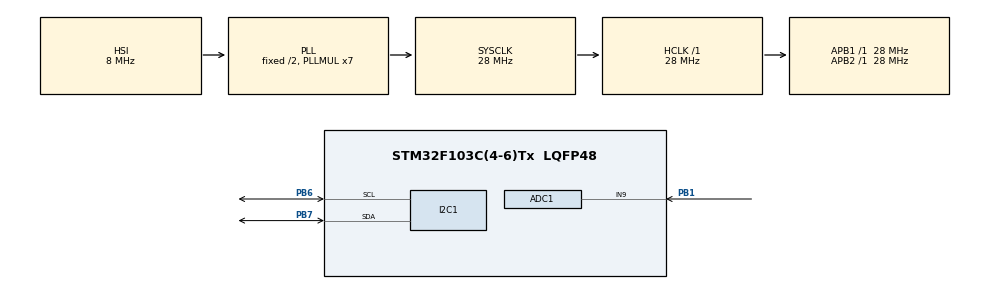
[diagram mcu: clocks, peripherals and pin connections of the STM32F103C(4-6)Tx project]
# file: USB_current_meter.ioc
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ADC1.Channel-4\#ChannelRegularConversion=ADC_CHANNEL_9
ADC1.ContinuousConvMode=DISABLE
ADC1.EnableRegularConversion=ENABLE
ADC1.NbrOfConversionFlag=1
ADC1.Rank-4\#ChannelRegularConversion=1
ADC1.SamplingTime-4\#ChannelRegularConversion=ADC_SAMPLETIME_1CYCLE_5
ADC1.master=1
I2C1.I2C_Mode=I2C_Fast
Mcu.Family=STM32F1
Mcu.Name=STM32F103C(4-6)Tx
Mcu.Package=LQFP48
NVIC.PriorityGroup=NVIC_PRIORITYGROUP_4
PB1.Signal=ADCx_IN9
PB6.Mode=I2C
PB6.Signal=I2C1_SCL
PB7.Mode=I2C
PB7.Signal=I2C1_SDA
ProjectManager.HeapSize=0x200
ProjectManager.StackSize=0x400
ProjectManager.TargetToolchain=STM32CubeIDE
RCC.AHBFreq_Value=28000000
RCC.APB1Freq_Value=28000000
RCC.APB1TimFreq_Value=28000000
RCC.APB2Freq_Value=28000000
RCC.APB2TimFreq_Value=28000000
RCC.HCLKFreq_Value=28000000
RCC.PLLMUL=RCC_PLL_MUL7
RCC.SYSCLKFreq_VALUE=28000000
RCC.SYSCLKSource=RCC_SYSCLKSOURCE_PLLCLK
RCC.USBFreq_Value=28000000
SH.ADCx_IN9.0=ADC1_IN9,IN9
VP_SYS_VS_ND.Mode=No_Debug
board=custom

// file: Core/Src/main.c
/* USER CODE BEGIN Header */
/**
  ******************************************************************************
  * @file           : main.c
  * @brief          : Main program body
  ******************************************************************************
  * @attention
  *
  * Copyright (c) 2025 STMicroelectronics.
  * All rights reserved.
  *
  * This software is licensed under terms that can be found in the LICENSE file
  * in the root directory of this software component.
  * If no LICENSE file comes with this software, it is provided AS-IS.
  *
  ******************************************************************************
  */
/* USER CODE END Header */
#include "main.h"

/* USER CODE BEGIN Includes */
#include "OLED.h"
#include <stdio.h>
/* USER CODE END Includes */

/* USER CODE BEGIN PTD */
#define DISPLAY_ITERATOR_MAXIMUM 500 //how frequently to display data
#define ADC_SAMPLE_COUNTDOWN_MAXIMUM 50000 //period of i average count

const float ADC_i_coef=0.83; //i=ADC*ADC_i_coef
unsigned long display_iterator=0;
unsigned long ADC_sample_countdown=ADC_SAMPLE_COUNTDOWN_MAXIMUM;
unsigned long i_sum=0; //sum of i measurment for average count

/* USER CODE END PTD */

ADC_HandleTypeDef hadc1;

I2C_HandleTypeDef hi2c1;

void SystemClock_Config(void);
static void MX_GPIO_Init(void);
static void MX_I2C1_Init(void);
static void MX_ADC1_Init(void);

/* USER CODE BEGIN 0 */
void oled_init(){
	HAL_Delay(100);
	OLED_Init(&hi2c1);
	FontSet(Segoe_UI_Rus_8);
	OLED_Clear(0);
/*	OLED_DrawVLine(0,0,20); //display shift test
	OLED_DrawVLine(1,0,30);
	OLED_DrawVLine(2,0,40);
	OLED_DrawVLine(3,0,50);
	OLED_DrawVLine(127,0,20);
	OLED_DrawVLine(128,0,30);
	OLED_DrawVLine(129,0,40);*/
	OLED_UpdateScreen();
	//while(1){};//display shift test
}

void init(){
	  oled_init();
	  HAL_ADCEx_Calibration_Start(&hadc1);
}

void loop(){

	HAL_ADC_Start(&hadc1); // запускаем преобразование сигнала АЦП
	HAL_ADC_PollForConversion(&hadc1, 100); // ожидаем окончания преобразования
	int i_meas = HAL_ADC_GetValue(&hadc1)*ADC_i_coef; // читаем полученное значение в переменную
	//HAL_ADC_Stop(&hadc1); // останавливаем АЦП (не обязательно)

    i_sum+=i_meas;

    OLED_DrawVLine(127*((float)(ADC_SAMPLE_COUNTDOWN_MAXIMUM-ADC_sample_countdown)/(float)ADC_SAMPLE_COUNTDOWN_MAXIMUM), 10, 1+(i_meas/10));

    display_iterator++;
    if(display_iterator>DISPLAY_ITERATOR_MAXIMUM){
    	OLED_DrawRectangleFill(0,0,127,7,0);
    	FontSet(Segoe_UI_Rus_8);
    	OLED_DrawStr("njr", 				1, 		0, 1);//ток
    	OLED_DrawNum(i_meas, 				20, 	0, 1);
    	OLED_DrawStr("vF", 					40, 	0, 1);//мА
    	OLED_DrawStr("ds,",		 			60, 	0, 1);//выборки
    	char buffer [64];
    	snprintf(buffer, sizeof(buffer), "%ld", ADC_sample_countdown);
    	//char * num_string = buffer; //String terminator is added by snprintf
    	OLED_DrawStr(buffer, 	80, 	0, 1);

    	OLED_UpdateOnePage(0); //0-7px h
    	OLED_UpdateOnePage(1); //8-15px h
    	OLED_UpdateOnePage(2); //16-23px h
    	OLED_UpdateOnePage(3); //24-31px h
    	OLED_UpdateOnePage(4); //32-39px h
    	OLED_UpdateOnePage(5); //39-46px h
    	display_iterator=0;
    }

    ADC_sample_countdown--;
    if(ADC_sample_countdown<=0){
    	OLED_Clear(0);
    	FontSet(Segoe_UI_Rus_12);
    	int i_average=i_sum/ADC_SAMPLE_COUNTDOWN_MAXIMUM;
    	OLED_DrawStr("chtly", 		1, 		50, 1);//средний
    	OLED_DrawNum(i_average, 	50, 	50, 1);
    	OLED_DrawStr("vF", 			80, 	50, 1);//мА
    	OLED_UpdateScreen();
    	ADC_sample_countdown=ADC_SAMPLE_COUNTDOWN_MAXIMUM;
    	i_sum=0;
    }

}

/* USER CODE END 0 */

int main(void)
{

  /* MCU Configuration--------------------------------------------------------*/

  /* Reset of all peripherals, Initializes the Flash interface and the Systick. */
  HAL_Init();

  /* Configure the system clock */
  SystemClock_Config();

  /* Initialize all configured peripherals */
  MX_GPIO_Init();
  MX_I2C1_Init();
  MX_ADC1_Init();
  /* USER CODE BEGIN 2 */
  init();

  /* USER CODE END 2 */

  /* Infinite loop */
  /* USER CODE BEGIN WHILE */
  while (1)
  {
	loop();
    /* USER CODE END WHILE */

  }
}

void SystemClock_Config(void)
{
  RCC_OscInitTypeDef RCC_OscInitStruct = {0};
  RCC_ClkInitTypeDef RCC_ClkInitStruct = {0};
  RCC_PeriphCLKInitTypeDef PeriphClkInit = {0};

  /** Initializes the RCC Oscillators according to the specified parameters
  * in the RCC_OscInitTypeDef structure.
  */
  RCC_OscInitStruct.OscillatorType = RCC_OSCILLATORTYPE_HSI;
  RCC_OscInitStruct.HSIState = RCC_HSI_ON;
  RCC_OscInitStruct.HSICalibrationValue = RCC_HSICALIBRATION_DEFAULT;
  RCC_OscInitStruct.PLL.PLLState = RCC_PLL_ON;
  RCC_OscInitStruct.PLL.PLLSource = RCC_PLLSOURCE_HSI_DIV2;
  RCC_OscInitStruct.PLL.PLLMUL = RCC_PLL_MUL7;
  if (HAL_RCC_OscConfig(&RCC_OscInitStruct) != HAL_OK)
  {
    Error_Handler();
  }

  /** Initializes the CPU, AHB and APB buses clocks
  */
  RCC_ClkInitStruct.ClockType = RCC_CLOCKTYPE_HCLK|RCC_CLOCKTYPE_SYSCLK
                              |RCC_CLOCKTYPE_PCLK1|RCC_CLOCKTYPE_PCLK2;
  RCC_ClkInitStruct.SYSCLKSource = RCC_SYSCLKSOURCE_PLLCLK;
  RCC_ClkInitStruct.AHBCLKDivider = RCC_SYSCLK_DIV1;
  RCC_ClkInitStruct.APB1CLKDivider = RCC_HCLK_DIV1;
  RCC_ClkInitStruct.APB2CLKDivider = RCC_HCLK_DIV1;

  if (HAL_RCC_ClockConfig(&RCC_ClkInitStruct, FLASH_LATENCY_1) != HAL_OK)
  {
    Error_Handler();
  }
  PeriphClkInit.PeriphClockSelection = RCC_PERIPHCLK_ADC;
  PeriphClkInit.AdcClockSelection = RCC_ADCPCLK2_DIV2;
  if (HAL_RCCEx_PeriphCLKConfig(&PeriphClkInit) != HAL_OK)
  {
    Error_Handler();
  }
}

static void MX_ADC1_Init(void)
{

  ADC_ChannelConfTypeDef sConfig = {0};

  /** Common config
  */
  hadc1.Instance = ADC1;
  hadc1.Init.ScanConvMode = ADC_SCAN_DISABLE;
  hadc1.Init.ContinuousConvMode = DISABLE;
  hadc1.Init.DiscontinuousConvMode = DISABLE;
  hadc1.Init.ExternalTrigConv = ADC_SOFTWARE_START;
  hadc1.Init.DataAlign = ADC_DATAALIGN_RIGHT;
  hadc1.Init.NbrOfConversion = 1;
  if (HAL_ADC_Init(&hadc1) != HAL_OK)
  {
    Error_Handler();
  }

  /** Configure Regular Channel
  */
  sConfig.Channel = ADC_CHANNEL_9;
  sConfig.Rank = ADC_REGULAR_RANK_1;
  sConfig.SamplingTime = ADC_SAMPLETIME_1CYCLE_5;
  if (HAL_ADC_ConfigChannel(&hadc1, &sConfig) != HAL_OK)
  {
    Error_Handler();
  }

}

static void MX_I2C1_Init(void)
{

  hi2c1.Instance = I2C1;
  hi2c1.Init.ClockSpeed = 400000;
  hi2c1.Init.DutyCycle = I2C_DUTYCYCLE_2;
  hi2c1.Init.OwnAddress1 = 0;
  hi2c1.Init.AddressingMode = I2C_ADDRESSINGMODE_7BIT;
  hi2c1.Init.DualAddressMode = I2C_DUALADDRESS_DISABLE;
  hi2c1.Init.OwnAddress2 = 0;
  hi2c1.Init.GeneralCallMode = I2C_GENERALCALL_DISABLE;
  hi2c1.Init.NoStretchMode = I2C_NOSTRETCH_DISABLE;
  if (HAL_I2C_Init(&hi2c1) != HAL_OK)
  {
    Error_Handler();
  }

}

static void MX_GPIO_Init(void)
{

  /* GPIO Ports Clock Enable */
  __HAL_RCC_GPIOB_CLK_ENABLE();

}

void Error_Handler(void)
{
  __disable_irq();
  while (1)
  {
  }
}
